# PT32x012xx register map
File version: 0.2
Registers are 32-bit, read-write, reset 0x0 unless marked. A register's access mark holds for its fields unless they carry their own. Offsets are from the block's base; [hi:lo] are bit positions.

## TIM4 — Low power timer
Base 0x40001C00
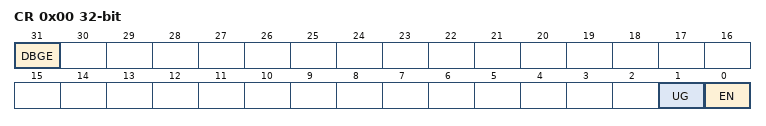
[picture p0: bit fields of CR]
0x00 CR access per field — Control Register
  [31] DBGE rw — TIM debug
  [1] UG wo — Counter Update generation
  [0] EN rw — Counter enable
0x40 SR1 — Status Register 1
  [0] ARF — auto reload flag
0x48 IER1 — Interrupt Enable Register 1
  [0] ARIE — Auto reload interrupt enable
0x58 PSCR — Prescaler Register
  [15:0] PSC — Prescaler value
0x60 CNTR ro — Counter Register
  [15:0] CNT — Counter value
0x64 ARR — Auto Reload Register
  [15:0] ARR — Auto reload value

## IWDG — Independent Watchdog
Base 0x40003000
0x00 RLR reset 0xFFFFFFFF — Reload Register
  [31:0] RL — Reload value
0x04 CNTR ro reset 0xFFFFFFFF — Counter Register
  [31:0] CNT — Counter value
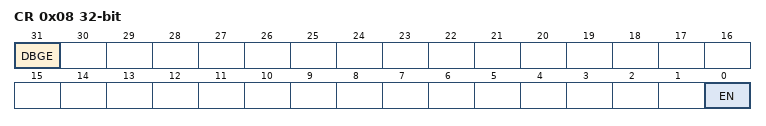
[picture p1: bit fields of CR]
0x08 CR — Control Register
  [31] DBGE — IWDG debug control
  [0] EN — enable
0x0C KR wo — Key Register
  [31:0] KEY — key value
0x10 SR ro — Status Register
  [0] HDF — hungry dog flag
0x3FC LR access per field reset 0x1 — Lock Register
  [31:0] KEY wo — lock key
  [0] LOCK ro — lock status

## I2C0 — Inter Integrated Circuit
Base 0x40005400
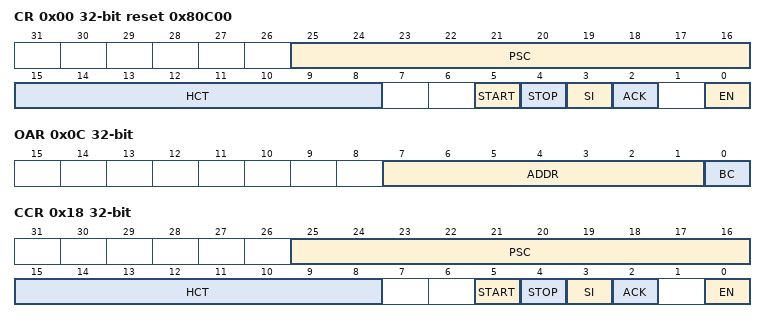
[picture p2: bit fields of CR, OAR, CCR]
0x00 CR access per field reset 0x80C00 — Control Register
  [25:16] PSC rw — Baud rate control
  [15:8] HCT rw — High level detection coefficient of time
  [5] START rw — Start generation
  [4] STOP rw — Stop generation
  [3] SI ro — I2C status flag
  [2] ACK rw — Acknowledge enable
  [0] EN rw — I2C enable
0x04 SR ro reset 0x1F — Status Register
  [4:0] SR — I2C bus status
0x08 DR — Data Register
  [7:0] DR — I2C data
0x0C OAR — Own Address Register
  [7:1] ADDR — I2C addr
  [0] BC — Broadcast response control
0x18 CCR wo — Control Clear Register
  [25:16] PSC — Clear prescaler
  [15:8] HCT — Clear high level detection time
  [5] START — Clear start generation
  [4] STOP — Clear stop generation
  [3] SI — Clear I2C interrupt flag
  [2] ACK — Clear Acknowledge control
  [0] EN — I2C disable

## LPUART0 — Low power Asynchronous Receiver Transmitter
Base 0x40004000
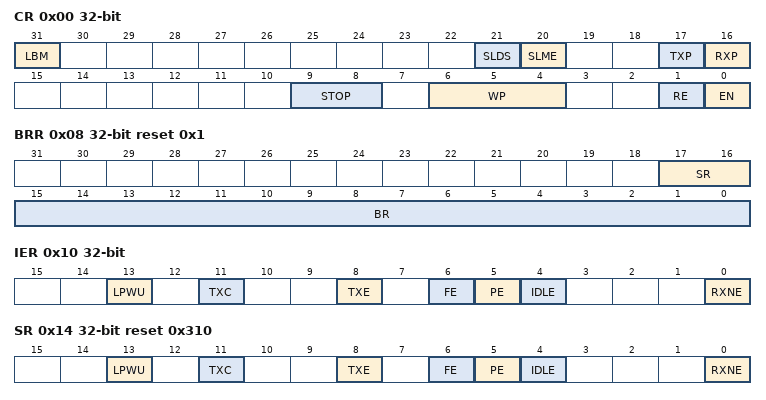
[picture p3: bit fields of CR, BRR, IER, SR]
0x00 CR — Control Register
  [31] LBM — loopback mode
  [21] SLDS — Single-line direction setting
  [20] SLME — Single-line mode enable
  [17] TXP — Transmitter polarity control
  [16] RXP — Receiver polarity control
  [9:8] STOP — Stop bit length
  [6:4] WP — Word length and parity config
  [1] RE — Receive enable
  [0] EN — LPUART enable
0x08 BRR reset 0x1 — Baud Rate Register
  [17:16] SR — Sample rate
  [15:0] BR — Baud rate control
0x10 IER — Interrupt Enable Register
  [13] LPWU — Low power wakeup interrupt enable
  [11] TXC — Transmit complete interrupt enable
  [8] TXE — Transmit FIFO empty interrupt enable
  [6] FE — frame error interrupt enable
  [5] PE — parity error interrupt enable
  [4] IDLE — Idle timeout interrupt enable
  [0] RXNE — Receive/Receive-FIFO not empty interrupt enable
0x14 SR reset 0x310 — Status Register
  [13] LPWU — Low power wakeup flag
  [11] TXC — Transmit complete flag
  [8] TXE ro — Transmit/Transmit-FIFO empty flag
  [6] FE — Frame error flag
  [5] PE — Parity error flag
  [4] IDLE — Idle overtime interrupt enable
  [0] RXNE ro — Receive/Receive-FIFO not empty flag
0x18 DR — Data Register
  [8:0] DR — LPUART data

## USART0 — Universal Synchronous Asynchronous Transceiver
Base 0x40010000
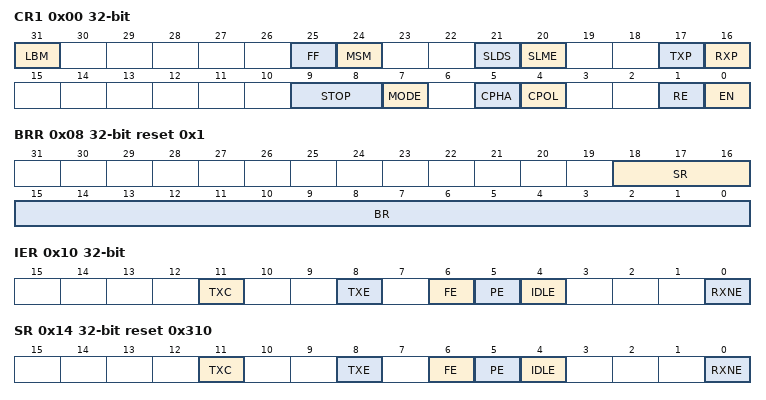
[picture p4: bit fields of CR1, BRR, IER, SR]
0x00 CR1 — Control Register 1
  [31] LBM — loopback mode
  [25] FF — Frame format
  [24] MSM — master-slave mode
  [21] SLDS — Single-line direction setting
  [20] SLME — Single-line mode enable
  [17] TXP — Transmitter polarity control
  [16] RXP — Receiver polarity control
  [9:8] STOP — Stop bit length
  [7] MODE — Mode selection
  [5] CPHA — Clock phase
  [4] CPOL — Clock polarity
  [1] RE — Receive enable
  [0] EN — USART enable
0x08 BRR reset 0x1 — Baud Rate Register
  [18:16] SR — Sample rate
  [15:0] BR — Baud rate control
0x10 IER — Interrupt Enable Register
  [11] TXC — Transmit complete interrupt enable
  [8] TXE — Transmit FIFO empty interrupt enable
  [6] FE — frame error interrupt enable
  [5] PE — parity error interrupt enable
  [4] IDLE — Idle timeout interrupt enable
  [0] RXNE — Receive/Receive-FIFO not empty interrupt enable
0x14 SR reset 0x310 — Status Register
  [11] TXC — Transmit complete flag
  [8] TXE ro — Transmit/Transmit-FIFO empty flag
  [6] FE — Frame error flag
  [5] PE — Parity error flag
  [4] IDLE — Idle overtime interrupt enable
  [0] RXNE ro — Receive/Receive-FIFO not empty flag
0x18 DR — Data Register
  [8:0] DR — LPUART data
0x1C CR3 — Control Register 3
  [23:0] CNT — Number of SCK clocks
